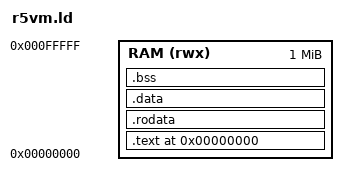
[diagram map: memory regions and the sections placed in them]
/* r5vm.ld */

OUTPUT_ARCH(riscv)
ENTRY(_start)

MEMORY
{
    RAM (rwx) : ORIGIN = 0x00000000, LENGTH = 1M
}

SECTIONS
{
    . = ORIGIN(RAM);

    .text : {
        *(.text.entry)
        *(.text*)
    } > RAM

    .rodata : {
        *(.rodata*)
    } > RAM

    .data : {
        _sdata = .;
        *(.data*)
        _edata = .;
    } > RAM AT > RAM

    .bss (NOLOAD) : {
        _sbss = .;
        *(.bss*)
        *(COMMON)
        _ebss = .;
    } > RAM

    . = ALIGN(4);
    _stack_top = ORIGIN(RAM) + LENGTH(RAM);
}

